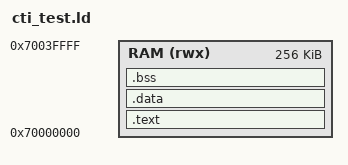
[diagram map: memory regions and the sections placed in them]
OUTPUT_FORMAT("elf32-littlearm")
OUTPUT_ARCH(arm)
ENTRY(_start)

MEMORY
{
    RAM (rwx) : ORIGIN = 0x70000000, LENGTH = 256K
}

SECTIONS
{
    .text : {
        KEEP(*(.vectors))
        *(.text*)
        *(.rodata*)
    } > RAM

    .data : {
        *(.data*)
    } > RAM

    .bss (NOLOAD) : {
        __bss_start__ = .;
        *(.bss*)
        *(COMMON)
        __bss_end__ = .;
    } > RAM

    _end = .;
}
